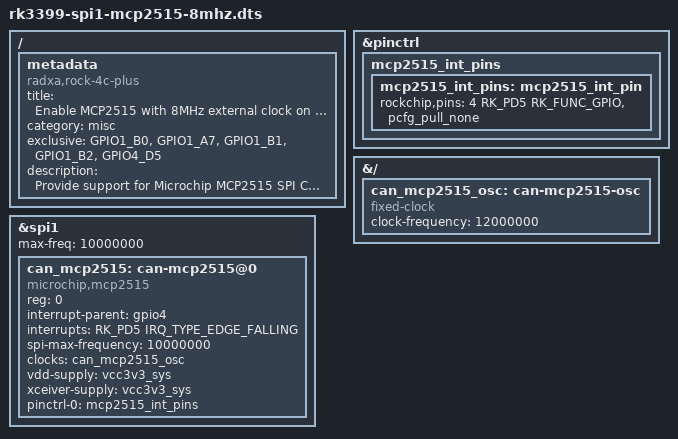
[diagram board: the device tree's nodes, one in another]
/dts-v1/;
/plugin/;

#include <dt-bindings/pinctrl/rockchip.h>
#include <dt-bindings/interrupt-controller/irq.h>

/ {
	metadata {
		title = "Enable MCP2515 with 8MHz external clock on SPI1";
		compatible = "radxa,rock-4c-plus";
		category = "misc";
		exclusive = "GPIO1_B0", "GPIO1_A7", "GPIO1_B1", "GPIO1_B2", "GPIO4_D5";
		description = "Provide support for Microchip MCP2515 SPI CAN controller.
Assumes 8MHz external clock.
Uses Pin 22 (GPIO4_D5) for INT.";
	};
};

&pinctrl {
	mcp2515_int_pins {
		mcp2515_int_pins: mcp2515_int_pin {
			rockchip,pins = <4 RK_PD5 RK_FUNC_GPIO &pcfg_pull_none>;
		};
	};
};

&{/} {
	can_mcp2515_osc: can-mcp2515-osc {
		compatible = "fixed-clock";
		clock-frequency = <12000000>;
		#clock-cells = <0>;
	};
};

&spi1 {
	status = "okay";
	max-freq = <10000000>;
	#address-cells = <1>;
	#size-cells = <0>;

	can_mcp2515: can-mcp2515@0 {
		status = "okay";
		compatible = "microchip,mcp2515";
		reg = <0>;
		interrupt-parent = <&gpio4>;
		interrupts = <RK_PD5 IRQ_TYPE_EDGE_FALLING>;
		spi-max-frequency = <10000000>;
		clocks = <&can_mcp2515_osc>;
		vdd-supply = <&vcc3v3_sys>;
		xceiver-supply = <&vcc3v3_sys>;
		pinctrl-names = "default";
		pinctrl-0 = <&mcp2515_int_pins>;
	};
};
